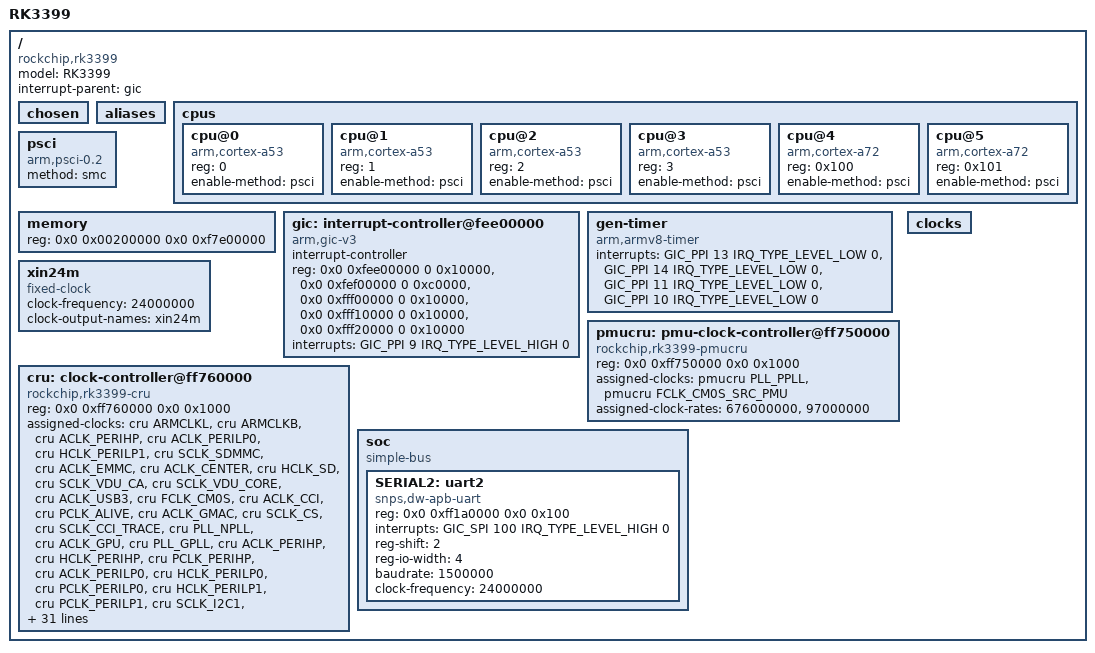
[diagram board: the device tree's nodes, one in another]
/**
 * Copyright (c) 2019 PT Switch.
 * All rights reserved.
 *
 * This program is free software; you can redistribute it and/or modify
 * it under the terms of the GNU General Public License as published by
 * the Free Software Foundation; either version 2, or (at your option)
 * any later version.
 *
 * This program is distributed in the hope that it will be useful,
 * but WITHOUT ANY WARRANTY; without even the implied warranty of
 * MERCHANTABILITY or FITNESS FOR A PARTICULAR PURPOSE.  See the
 * GNU General Public License for more details.
 *
 * You should have received a copy of the GNU General Public License
 * along with this program; if not, write to the Free Software
 * Foundation, Inc., 675 Mass Ave, Cambridge, MA 02139, USA.
 *
 * @file rk3399.dtsi
 * @author Andy Dean (acd@kynesim.co.uk)
 * @brief RK3399 SOC device tree
 */

#include <dt-bindings/interrupt-controller/arm-gic.h>
#include <dt-bindings/clock/rk3399-cru.h>


/ {
	#address-cells = <2>;
	#size-cells = <2>;
	compatible = "rockchip,rk3399";
	model = "RK3399";
	interrupt-parent = <&gic>;

	chosen { };
	aliases { };

	cpus {
		#address-cells = <1>;
		#size-cells = <0>;

		cpu@0 {
			device_type = "cpu";
			compatible = "arm,cortex-a53";
			reg = <0>;
			enable-method = "psci";
		};

		cpu@1 {
			device_type = "cpu";
			compatible = "arm,cortex-a53";
			reg = <1>;
			enable-method = "psci";
		};

		cpu@2 {
			device_type = "cpu";
			compatible = "arm,cortex-a53";
			reg = <2>;
			enable-method = "psci";
		};

		cpu@3 {
			device_type = "cpu";
			compatible = "arm,cortex-a53";
			reg = <3>;
			enable-method = "psci";
		};

		cpu@4 {
			device_type = "cpu";
			compatible = "arm,cortex-a72";
			reg = <0x100>;
			enable-method = "psci";
		};

		cpu@5 {
			device_type = "cpu";
			compatible = "arm,cortex-a72";
			reg = <0x101>;
			enable-method = "psci";
		};

	};

	psci {
		 compatible = "arm,psci-0.2";
		 method = "smc";
	};

	memory {
		device_type = "memory";
		/* 4 GB, less 2MB at start reserved for Arm Trusted
		 * Firmware, and 130MB at end used for I/O address space.
		 */
		reg = <0x0 0x00200000 0x0 0xf7e00000>;
	};

	gic: interrupt-controller@fee00000 {
		compatible = "arm,gic-v3";
		#interrupt-cells = <4>;
		#address-cells = <2>;
		#size-cells = <2>;
		ranges;
		interrupt-controller;

		reg = <0x0 0xfee00000 0 0x10000>, /* GICD */
			<0x0 0xfef00000 0 0xc0000>, /* GICR */
			<0x0 0xfff00000 0 0x10000>, /* GICC */
			<0x0 0xfff10000 0 0x10000>, /* GICH */
			<0x0 0xfff20000 0 0x10000>; /* GICV */
			interrupts = <GIC_PPI 9 IRQ_TYPE_LEVEL_HIGH 0>;
	};

	gen-timer { /* Generic Timer */
		compatible = "arm,armv8-timer";
		interrupts = <GIC_PPI 13 IRQ_TYPE_LEVEL_LOW 0>, // PHYS_SECURE_PPI
				<GIC_PPI 14 IRQ_TYPE_LEVEL_LOW 0>, // PHYS_NONSECURE_PPI
				<GIC_PPI 11 IRQ_TYPE_LEVEL_LOW 0>, // VIRT_PPI
				<GIC_PPI 10 IRQ_TYPE_LEVEL_LOW 0>; // HYP_PPI
	};

	xin24m: xin24m {
		compatible = "fixed-clock";
		clock-frequency = <24000000>;
		clock-output-names = "xin24m";
		#clock-cells = <0>;
	};

	pmucru: pmu-clock-controller@ff750000 {
		compatible = "rockchip,rk3399-pmucru";
		reg = <0x0 0xff750000 0x0 0x1000>;
		#clock-cells = <1>;
		#reset-cells = <1>;
		assigned-clocks = <&pmucru PLL_PPLL>, <&pmucru FCLK_CM0S_SRC_PMU>;
		assigned-clock-rates = <676000000>, <97000000>;
	};

	cru: clock-controller@ff760000 {
		compatible = "rockchip,rk3399-cru";
		reg = <0x0 0xff760000 0x0 0x1000>;
		#clock-cells = <1>;
		#reset-cells = <1>;
		assigned-clocks =
			<&cru ARMCLKL>, <&cru ARMCLKB>,
			<&cru ACLK_PERIHP>, <&cru ACLK_PERILP0>,
			<&cru HCLK_PERILP1>, <&cru SCLK_SDMMC>,
			<&cru ACLK_EMMC>, <&cru ACLK_CENTER>,
			<&cru HCLK_SD>, <&cru SCLK_VDU_CA>,
			<&cru SCLK_VDU_CORE>, <&cru ACLK_USB3>,
			<&cru FCLK_CM0S>, <&cru ACLK_CCI>,
			<&cru PCLK_ALIVE>, <&cru ACLK_GMAC>,
			<&cru SCLK_CS>, <&cru SCLK_CCI_TRACE>,
			<&cru PLL_NPLL>, <&cru ACLK_GPU>,
			<&cru PLL_GPLL>, <&cru ACLK_PERIHP>,
			<&cru HCLK_PERIHP>, <&cru PCLK_PERIHP>,
			<&cru ACLK_PERILP0>, <&cru HCLK_PERILP0>,
			<&cru PCLK_PERILP0>, <&cru HCLK_PERILP1>,
			<&cru PCLK_PERILP1>, <&cru SCLK_I2C1>,
			<&cru SCLK_I2C2>, <&cru SCLK_I2C3>,
			<&cru SCLK_I2C5>, <&cru SCLK_I2C6>,
			<&cru SCLK_I2C7>, <&cru SCLK_SPI0>,
			<&cru SCLK_SPI1>, <&cru SCLK_SPI2>,
			<&cru SCLK_SPI4>, <&cru SCLK_SPI5>,
			<&cru ACLK_GIC>, <&cru ACLK_ISP0>,
			<&cru ACLK_ISP1>, <&cru SCLK_VOP0_PWM>,
			<&cru SCLK_VOP1_PWM>, <&cru PCLK_EDP>,
			<&cru ACLK_HDCP>, <&cru ACLK_VIO>,
			<&cru SCLK_CRYPTO0>,
			<&cru SCLK_CRYPTO1>, <&cru SCLK_EMMC>,
			<&cru ACLK_IEP>, <&cru ACLK_RGA>,
			<&cru SCLK_RGA_CORE>, <&cru ACLK_VDU>,
			<&cru ACLK_VCODEC>,
			<&cru ACLK_VOP0>,
			<&cru HCLK_VOP0>, <&cru ACLK_VOP1>,
			<&cru HCLK_VOP1>,
			<&cru SCLK_DP_CORE>, <&cru SCLK_SPDIF_REC_DPTX>,
			<&cru SCLK_TSADC>;
		assigned-clock-rates =
			<816000000>, <816000000>,
			 <75000000>, <50000000>,
			 <50000000>, <50000000>,
			 <50000000>, <100000000>,
			 <50000000>, <150000000>,
			 <150000000>, <150000000>,
			 <50000000>, <600000000>,
			 <50000000>, <100000000>,
			 <75000000>, <75000000>,
			 <600000000>, <200000000>,
			 <800000000>, <150000000>,
			 <75000000>, <37500000>,
			 <300000000>, <100000000>,
			 <50000000>, <100000000>,
			 <50000000>, <100000000>,
			 <100000000>, <100000000>,
			 <100000000>, <100000000>,
			 <100000000>, <50000000>,
			 <50000000>, <50000000>,
			 <50000000>, <50000000>,
			 <200000000>, <400000000>,
			 <400000000>, <100000000>,
			 <100000000>, <100000000>,
			 <400000000>, <400000000>,
			 <100000000>,
			 <200000000>, <200000000>,
			 <400000000>, <400000000>,
			 <400000000>, <300000000>,
			 <400000000>,
			 <400000000>,
			 <100000000>, <400000000>,
			 <100000000>,
			 <100000000>, <200000000>,
			 <750000>;
	};

	soc: soc {
		#address-cells = <2>;
		#size-cells = <2>;
		compatible = "simple-bus";

		SERIAL2: uart2 {
			compatible = "snps,dw-apb-uart";
			reg = <0x0 0xff1a0000 0x0 0x100>;
			interrupts = <GIC_SPI 100 IRQ_TYPE_LEVEL_HIGH 0>;
			reg-shift = <2>;
			reg-io-width = <4>;
			baudrate = <1500000>;
			clock-frequency = <24000000>;
		};
	};

	clocks {
		#address-cells = <1>;
		#size-cells = <0>;

	};
};
